VERSION ""

NS_ :

BS_:

BU_:

BO_ 3221225472 VECTOR__INDEPENDENT_SIG_MSG: 0 Vector__XXX
 SG_ ang_heading : 40|16@1- (0.01,0) [-327.68|327.67] "rad" Vector__XXX
 SG_ pos_y : 20|20@1- (0.01,0) [-5242.88|5242.87] "m" Vector__XXX
 SG_ pos_x : 0|20@1- (0.01,0) [-5242.88|5242.87] "m" Vector__XXX
 SG_ yaw_rate : 36|12@1- (0.025,0) [-51.2|51.175] "rps" Vector__XXX
 SG_ velocity_long : 24|12@1- (0.05,0) [-102.4|102.35] "mps" Vector__XXX
 SG_ velocity_lat : 12|12@1- (0.05,0) [-102.4|102.35] "mps" Vector__XXX
 SG_ motor_angle : 48|12@1- (0.5,0) [-255|255] "rad" Vector__XXX
 SG_ acceleration : 0|12@1- (0.025,0) [-51.2|51.175] "mps2" Vector__XXX
 SG_ rc_base_sync_check : 0|1@1+ (1,0) [0|0] "" Vector__XXX
 SG_ rc_lte_rssi : 1|8@1- (1,0) [0|0] "dBm" Vector__XXX
 SG_ duty_cycle_fbk : 48|8@1- (1,0) [-100|100] "%" Vector__XXX
 SG_ duty_cycle_dmd : 40|8@1- (1,0) [-100|100] "%" Vector__XXX
 SG_ steering_motor_ang_avg_fdbk : 0|11@1- (0.5,0) [-1024|1023] "deg" Vector__XXX

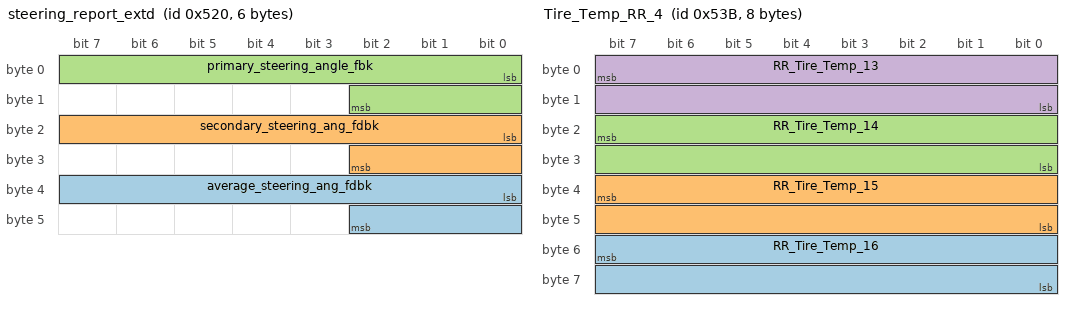
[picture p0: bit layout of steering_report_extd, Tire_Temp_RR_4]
BO_ 1312 steering_report_extd: 6 Vector__XXX
 SG_ average_steering_ang_fdbk : 32|11@1- (0.5,0) [-1024|1023] "deg" Vector__XXX
 SG_ secondary_steering_ang_fdbk : 16|11@1- (0.5,0) [-1024|1023] "deg" Vector__XXX
 SG_ primary_steering_angle_fbk : 0|11@1- (0.5,0) [-1024|1023] "deg" Vector__XXX

BO_ 1339 Tire_Temp_RR_4: 8 Vector__XXX
 SG_ RR_Tire_Temp_16 : 55|16@0+ (0.1,-100) [-100|6453.5] "degC" Vector__XXX
 SG_ RR_Tire_Temp_15 : 39|16@0+ (0.1,-100) [-100|6453.5] "degC" Vector__XXX
 SG_ RR_Tire_Temp_14 : 23|16@0+ (0.1,-100) [-100|6453.5] "degC" Vector__XXX
 SG_ RR_Tire_Temp_13 : 7|16@0+ (0.1,-100) [-100|6453.5] "degC" Vector__XXX

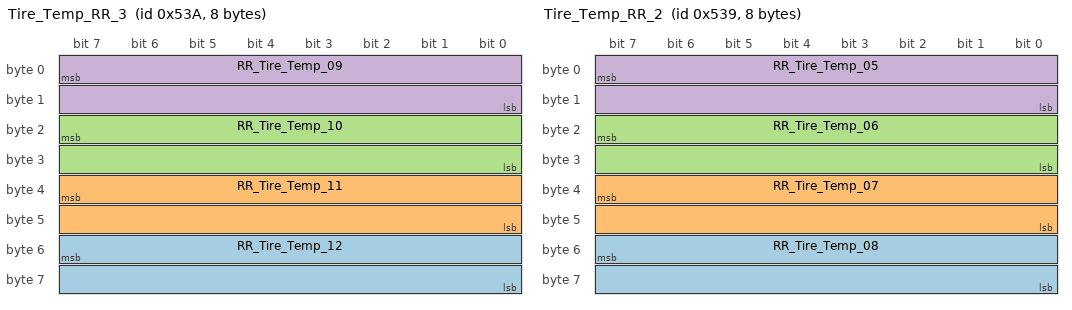
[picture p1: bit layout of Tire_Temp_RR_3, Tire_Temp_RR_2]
BO_ 1338 Tire_Temp_RR_3: 8 Vector__XXX
 SG_ RR_Tire_Temp_12 : 55|16@0+ (0.1,-100) [-100|6453.5] "degC" Vector__XXX
 SG_ RR_Tire_Temp_11 : 39|16@0+ (0.1,-100) [-100|6453.5] "degC" Vector__XXX
 SG_ RR_Tire_Temp_10 : 23|16@0+ (0.1,-100) [-100|6453.5] "degC" Vector__XXX
 SG_ RR_Tire_Temp_09 : 7|16@0+ (0.1,-100) [-100|6453.5] "degC" Vector__XXX

BO_ 1337 Tire_Temp_RR_2: 8 Vector__XXX
 SG_ RR_Tire_Temp_08 : 55|16@0+ (0.1,-100) [-100|6453.5] "degC" Vector__XXX
 SG_ RR_Tire_Temp_07 : 39|16@0+ (0.1,-100) [-100|6453.5] "degC" Vector__XXX
 SG_ RR_Tire_Temp_06 : 23|16@0+ (0.1,-100) [-100|6453.5] "degC" Vector__XXX
 SG_ RR_Tire_Temp_05 : 7|16@0+ (0.1,-100) [-100|6453.5] "degC" Vector__XXX

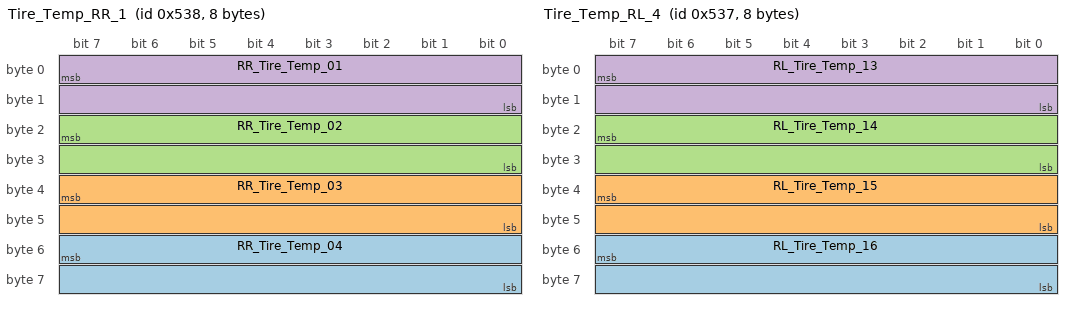
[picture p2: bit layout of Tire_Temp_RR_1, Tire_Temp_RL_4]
BO_ 1336 Tire_Temp_RR_1: 8 Vector__XXX
 SG_ RR_Tire_Temp_04 : 55|16@0+ (0.1,-100) [-100|6453.5] "degC" Vector__XXX
 SG_ RR_Tire_Temp_03 : 39|16@0+ (0.1,-100) [-100|6453.5] "degC" Vector__XXX
 SG_ RR_Tire_Temp_02 : 23|16@0+ (0.1,-100) [-100|6453.5] "degC" Vector__XXX
 SG_ RR_Tire_Temp_01 : 7|16@0+ (0.1,-100) [-100|6453.5] "degC" Vector__XXX

BO_ 1335 Tire_Temp_RL_4: 8 Vector__XXX
 SG_ RL_Tire_Temp_16 : 55|16@0+ (0.1,-100) [-100|6453.5] "degC" Vector__XXX
 SG_ RL_Tire_Temp_15 : 39|16@0+ (0.1,-100) [-100|6453.5] "degC" Vector__XXX
 SG_ RL_Tire_Temp_14 : 23|16@0+ (0.1,-100) [-100|6453.5] "degC" Vector__XXX
 SG_ RL_Tire_Temp_13 : 7|16@0+ (0.1,-100) [-100|6453.5] "degC" Vector__XXX

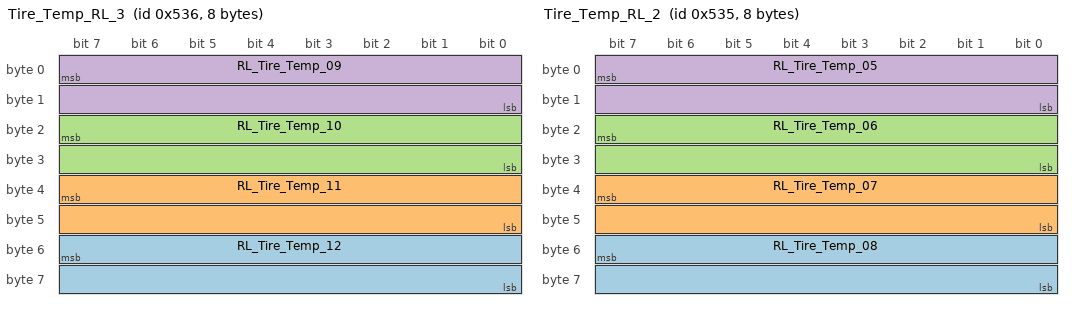
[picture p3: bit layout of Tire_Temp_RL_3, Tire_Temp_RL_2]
BO_ 1334 Tire_Temp_RL_3: 8 Vector__XXX
 SG_ RL_Tire_Temp_12 : 55|16@0+ (0.1,-100) [-100|6453.5] "degC" Vector__XXX
 SG_ RL_Tire_Temp_11 : 39|16@0+ (0.1,-100) [-100|6453.5] "degC" Vector__XXX
 SG_ RL_Tire_Temp_10 : 23|16@0+ (0.1,-100) [-100|6453.5] "degC" Vector__XXX
 SG_ RL_Tire_Temp_09 : 7|16@0+ (0.1,-100) [-100|6453.5] "degC" Vector__XXX

BO_ 1333 Tire_Temp_RL_2: 8 Vector__XXX
 SG_ RL_Tire_Temp_08 : 55|16@0+ (0.1,-100) [-100|6453.5] "degC" Vector__XXX
 SG_ RL_Tire_Temp_07 : 39|16@0+ (0.1,-100) [-100|6453.5] "degC" Vector__XXX
 SG_ RL_Tire_Temp_06 : 23|16@0+ (0.1,-100) [-100|6453.5] "degC" Vector__XXX
 SG_ RL_Tire_Temp_05 : 7|16@0+ (0.1,-100) [-100|6453.5] "degC" Vector__XXX

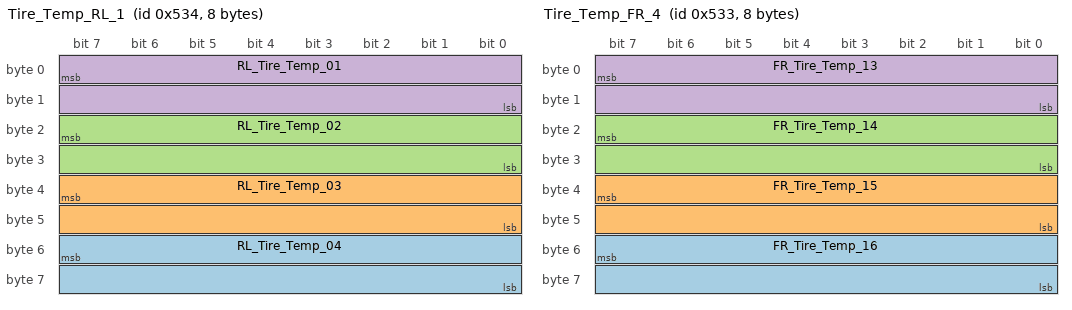
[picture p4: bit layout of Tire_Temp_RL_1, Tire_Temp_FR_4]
BO_ 1332 Tire_Temp_RL_1: 8 Vector__XXX
 SG_ RL_Tire_Temp_04 : 55|16@0+ (0.1,-100) [-100|6453.5] "degC" Vector__XXX
 SG_ RL_Tire_Temp_03 : 39|16@0+ (0.1,-100) [-100|6453.5] "degC" Vector__XXX
 SG_ RL_Tire_Temp_02 : 23|16@0+ (0.1,-100) [-100|6453.5] "degC" Vector__XXX
 SG_ RL_Tire_Temp_01 : 7|16@0+ (0.1,-100) [-100|6453.5] "degC" Vector__XXX

BO_ 1331 Tire_Temp_FR_4: 8 Vector__XXX
 SG_ FR_Tire_Temp_16 : 55|16@0+ (0.1,-100) [-100|6453.5] "degC" Vector__XXX
 SG_ FR_Tire_Temp_15 : 39|16@0+ (0.1,-100) [-100|6453.5] "degC" Vector__XXX
 SG_ FR_Tire_Temp_14 : 23|16@0+ (0.1,-100) [-100|6453.5] "degC" Vector__XXX
 SG_ FR_Tire_Temp_13 : 7|16@0+ (0.1,-100) [-100|6453.5] "degC" Vector__XXX

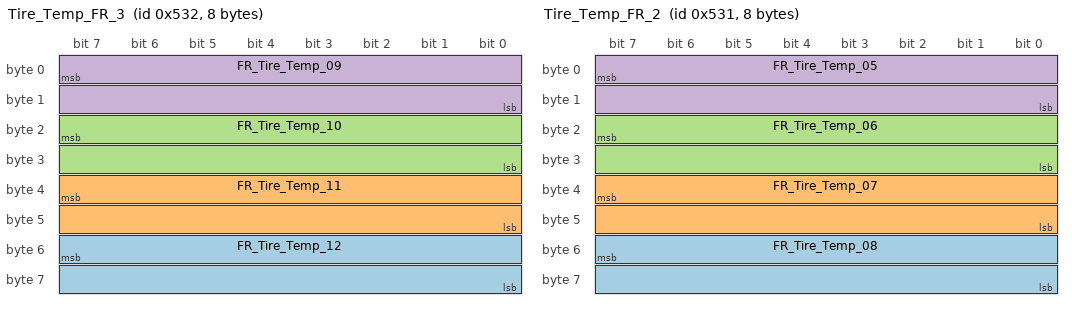
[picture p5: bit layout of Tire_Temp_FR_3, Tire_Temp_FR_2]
BO_ 1330 Tire_Temp_FR_3: 8 Vector__XXX
 SG_ FR_Tire_Temp_12 : 55|16@0+ (0.1,-100) [-100|6453.5] "degC" Vector__XXX
 SG_ FR_Tire_Temp_11 : 39|16@0+ (0.1,-100) [-100|6453.5] "degC" Vector__XXX
 SG_ FR_Tire_Temp_10 : 23|16@0+ (0.1,-100) [-100|6453.5] "degC" Vector__XXX
 SG_ FR_Tire_Temp_09 : 7|16@0+ (0.1,-100) [-100|6453.5] "degC" Vector__XXX

BO_ 1329 Tire_Temp_FR_2: 8 Vector__XXX
 SG_ FR_Tire_Temp_08 : 55|16@0+ (0.1,-100) [-100|6453.5] "degC" Vector__XXX
 SG_ FR_Tire_Temp_07 : 39|16@0+ (0.1,-100) [-100|6453.5] "degC" Vector__XXX
 SG_ FR_Tire_Temp_06 : 23|16@0+ (0.1,-100) [-100|6453.5] "degC" Vector__XXX
 SG_ FR_Tire_Temp_05 : 7|16@0+ (0.1,-100) [-100|6453.5] "degC" Vector__XXX

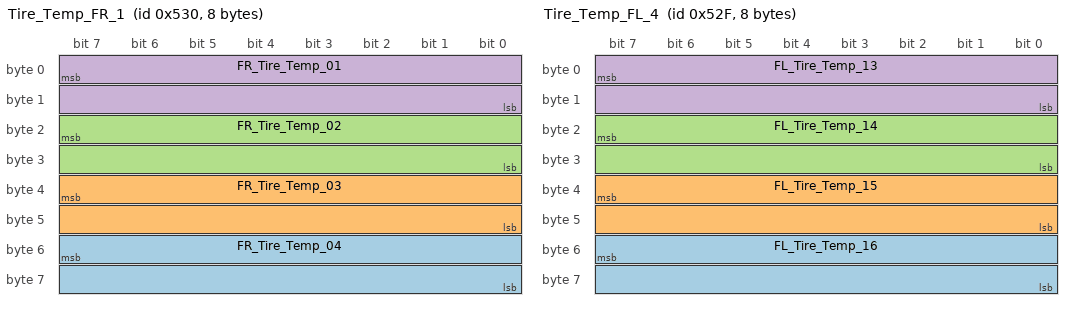
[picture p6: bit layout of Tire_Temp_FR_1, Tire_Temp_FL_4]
BO_ 1328 Tire_Temp_FR_1: 8 Vector__XXX
 SG_ FR_Tire_Temp_04 : 55|16@0+ (0.1,-100) [-100|6453.5] "degC" Vector__XXX
 SG_ FR_Tire_Temp_03 : 39|16@0+ (0.1,-100) [-100|6453.5] "degC" Vector__XXX
 SG_ FR_Tire_Temp_02 : 23|16@0+ (0.1,-100) [-100|6453.5] "degC" Vector__XXX
 SG_ FR_Tire_Temp_01 : 7|16@0+ (0.1,-100) [-100|6453.5] "degC" Vector__XXX

BO_ 1327 Tire_Temp_FL_4: 8 Vector__XXX
 SG_ FL_Tire_Temp_16 : 55|16@0+ (0.1,-100) [-100|6453.5] "degC" Vector__XXX
 SG_ FL_Tire_Temp_15 : 39|16@0+ (0.1,-100) [-100|6453.5] "degC" Vector__XXX
 SG_ FL_Tire_Temp_14 : 23|16@0+ (0.1,-100) [-100|6453.5] "degC" Vector__XXX
 SG_ FL_Tire_Temp_13 : 7|16@0+ (0.1,-100) [-100|6453.5] "degC" Vector__XXX

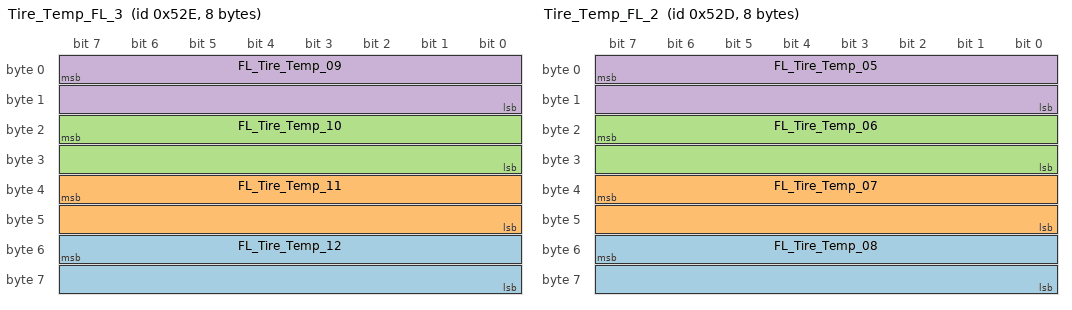
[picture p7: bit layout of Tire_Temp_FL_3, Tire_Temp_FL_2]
BO_ 1326 Tire_Temp_FL_3: 8 Vector__XXX
 SG_ FL_Tire_Temp_12 : 55|16@0+ (0.1,-100) [-100|6453.5] "degC" Vector__XXX
 SG_ FL_Tire_Temp_11 : 39|16@0+ (0.1,-100) [-100|6453.5] "degC" Vector__XXX
 SG_ FL_Tire_Temp_10 : 23|16@0+ (0.1,-100) [-100|6453.5] "degC" Vector__XXX
 SG_ FL_Tire_Temp_09 : 7|16@0+ (0.1,-100) [-100|6453.5] "degC" Vector__XXX

BO_ 1325 Tire_Temp_FL_2: 8 Vector__XXX
 SG_ FL_Tire_Temp_08 : 55|16@0+ (0.1,-100) [-100|6453.5] "degC" Vector__XXX
 SG_ FL_Tire_Temp_07 : 39|16@0+ (0.1,-100) [-100|6453.5] "degC" Vector__XXX
 SG_ FL_Tire_Temp_06 : 23|16@0+ (0.1,-100) [-100|6453.5] "degC" Vector__XXX
 SG_ FL_Tire_Temp_05 : 7|16@0+ (0.1,-100) [-100|6453.5] "degC" Vector__XXX

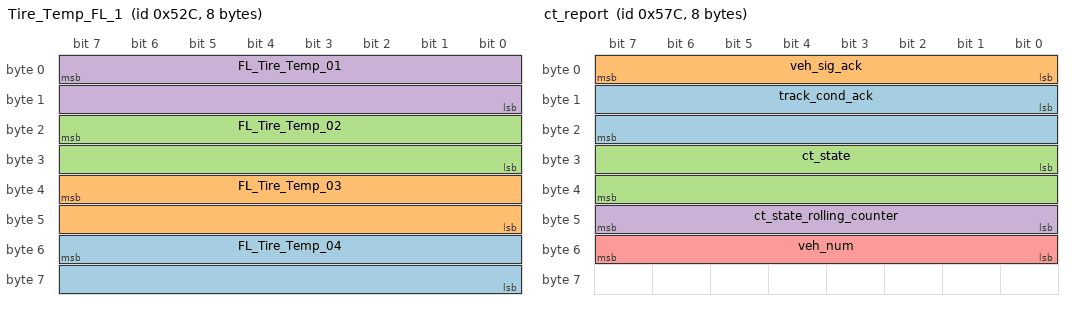
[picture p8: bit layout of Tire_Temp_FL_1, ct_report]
BO_ 1324 Tire_Temp_FL_1: 8 Vector__XXX
 SG_ FL_Tire_Temp_04 : 55|16@0+ (0.1,-100) [-100|6453.5] "degC" Vector__XXX
 SG_ FL_Tire_Temp_03 : 39|16@0+ (0.1,-100) [-100|6453.5] "degC" Vector__XXX
 SG_ FL_Tire_Temp_02 : 23|16@0+ (0.1,-100) [-100|6453.5] "degC" Vector__XXX
 SG_ FL_Tire_Temp_01 : 7|16@0+ (0.1,-100) [-100|6453.5] "degC" Vector__XXX

BO_ 1323 Tire_Pressure_RR: 4 Vector__XXX
 SG_ RR_Tire_Pressure_Gauge : 23|16@0+ (1,0) [0|65535] "mbar" Vector__XXX
 SG_ RR_Tire_Pressure : 7|16@0+ (1,0) [0|65535] "mbar" Vector__XXX

BO_ 1322 Tire_Pressure_RL: 4 Vector__XXX
 SG_ RL_Tire_Pressure_Gauge : 23|16@0+ (1,0) [0|65535] "mbar" Vector__XXX
 SG_ RL_Tire_Pressure : 7|16@0+ (1,0) [0|65535] "mbar" Vector__XXX

BO_ 1321 Tire_Pressure_FR: 4 Vector__XXX
 SG_ FR_Tire_Pressure_Gauge : 23|16@0+ (1,0) [0|65535] "mbar" Vector__XXX
 SG_ FR_Tire_Pressure : 7|16@0+ (1,0) [0|65535] "mbar" Vector__XXX

BO_ 1320 Tire_Pressure_FL: 4 Vector__XXX
 SG_ FL_Tire_Pressure_Gauge : 23|16@0+ (1,0) [0|65535] "mbar" Vector__XXX
 SG_ FL_Tire_Pressure : 7|16@0+ (1,0) [0|65535] "mbar" Vector__XXX

BO_ 1403 gear_shift_cmd: 8 Vector__XXX
 SG_ desired_gear : 0|8@1+ (1,0) [0|0] "" Vector__XXX

BO_ 1404 ct_report: 8 Vector__XXX
 SG_ track_cond_ack : 8|16@1+ (1,0) [0|0] "" Vector__XXX
 SG_ veh_sig_ack : 0|8@1+ (1,0) [0|0] "" Vector__XXX
 SG_ ct_state : 24|16@1+ (1,0) [0|0] "" Vector__XXX
 SG_ ct_state_rolling_counter : 40|8@1+ (1,0) [0|9] "" Vector__XXX
 SG_ veh_num : 48|8@1+ (1,0) [0|0] "" Vector__XXX

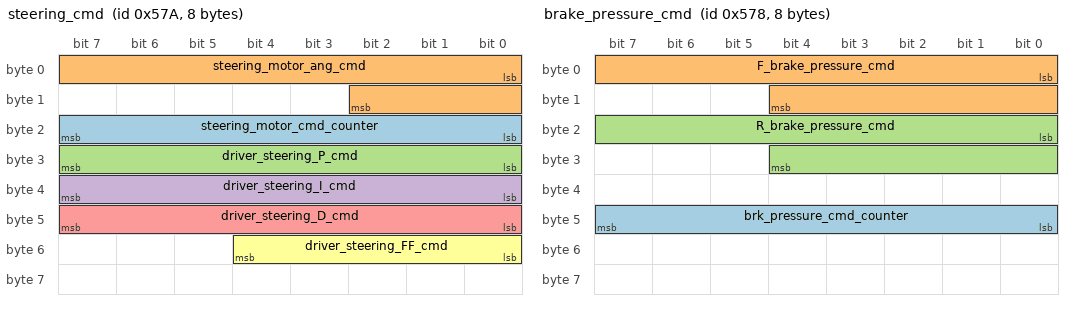
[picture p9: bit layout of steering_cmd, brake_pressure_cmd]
BO_ 1402 steering_cmd: 8 Vector__XXX
 SG_ steering_motor_cmd_counter : 16|8@1+ (1,0) [0|255] "" Vector__XXX
 SG_ steering_motor_ang_cmd : 0|11@1- (0.5,0) [-1024|1023] "deg" Vector__XXX
 SG_ driver_steering_P_cmd : 24|8@1+ (0.1,0) [0|0] "" Vector__XXX
 SG_ driver_steering_I_cmd : 32|8@1+ (0.1,0) [0|0] "" Vector__XXX
 SG_ driver_steering_D_cmd : 40|8@1+ (0.01,0) [0|0] "" Vector__XXX
 SG_ driver_steering_FF_cmd : 48|5@1+ (0.1,0) [0|3.1] "" Vector__XXX

BO_ 1401 accelerator_cmd: 8 Vector__XXX
 SG_ acc_pedal_cmd_counter : 16|8@1+ (1,0) [0|255] "" Vector__XXX
 SG_ acc_pedal_cmd : 0|16@1- (0.01,0) [-150|655.35] "%" Vector__XXX

BO_ 1400 brake_pressure_cmd: 8 Vector__XXX
 SG_ brk_pressure_cmd_counter : 40|8@1+ (1,0) [0|255] "" Vector__XXX
 SG_ F_brake_pressure_cmd : 0|13@1+ (1,0) [0|8191] "" Vector__XXX
 SG_ R_brake_pressure_cmd : 16|13@1+ (1,0) [0|8191] "" Vector__XXX

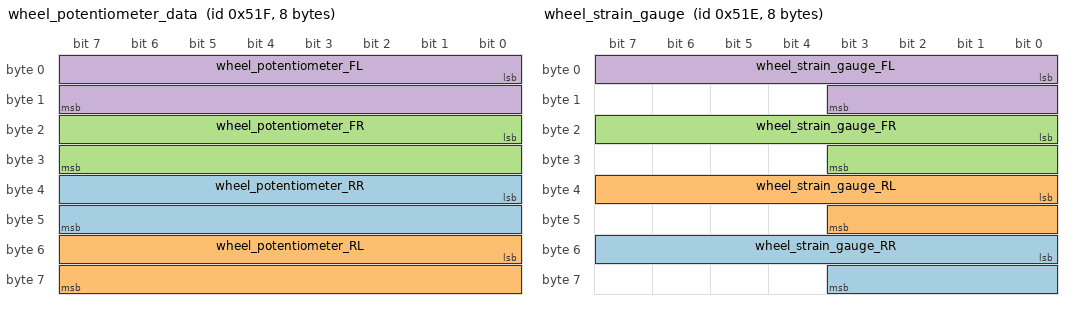
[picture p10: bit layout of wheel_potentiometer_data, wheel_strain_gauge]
BO_ 1311 wheel_potentiometer_data: 8 Vector__XXX
 SG_ wheel_potentiometer_RR : 32|16@1+ (0.01,0) [0|0] "" Vector__XXX
 SG_ wheel_potentiometer_RL : 48|16@1+ (0.01,0) [0|0] "" Vector__XXX
 SG_ wheel_potentiometer_FR : 16|16@1+ (0.01,0) [0|0] "" Vector__XXX
 SG_ wheel_potentiometer_FL : 0|16@1+ (0.01,0) [0|0] "" Vector__XXX

BO_ 1310 wheel_strain_gauge: 8 Vector__XXX
 SG_ wheel_strain_gauge_RR : 48|12@1+ (10,0) [0|8190] "" Vector__XXX
 SG_ wheel_strain_gauge_RL : 32|12@1+ (10,0) [0|8190] "" Vector__XXX
 SG_ wheel_strain_gauge_FR : 16|12@1+ (10,0) [0|8190] "" Vector__XXX
 SG_ wheel_strain_gauge_FL : 0|12@1+ (10,0) [0|8190] "" Vector__XXX

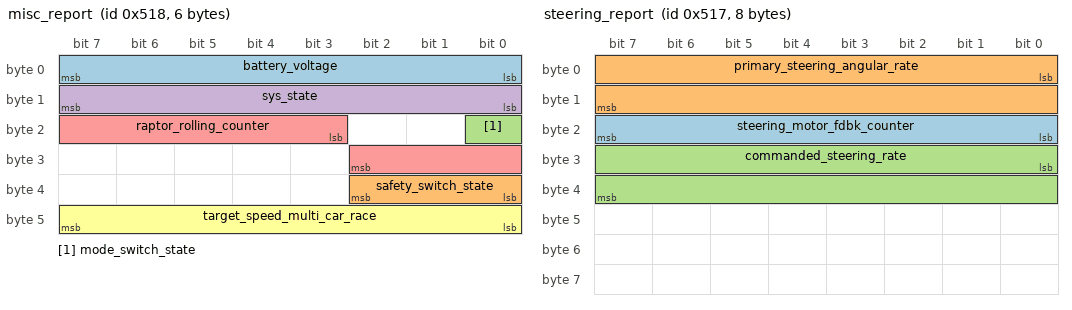
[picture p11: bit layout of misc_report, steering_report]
BO_ 1304 misc_report: 6 Vector__XXX
 SG_ battery_voltage : 0|8@1+ (0.1,0) [0|0] "V" Vector__XXX
 SG_ safety_switch_state : 32|3@1+ (1,0) [0|0] "" Vector__XXX
 SG_ mode_switch_state : 16|1@1+ (1,0) [0|0] "" Vector__XXX
 SG_ sys_state : 8|8@1+ (1,0) [0|0] "" Vector__XXX
 SG_ raptor_rolling_counter : 19|8@1+ (1,0) [0|0] "" Vector__XXX
 SG_ target_speed_multi_car_race : 40|8@1+ (1,0) [0|0] "mph" Vector__XXX

BO_ 1303 steering_report: 8 Vector__XXX
 SG_ steering_motor_fdbk_counter : 16|8@1+ (1,0) [0|255] "" Vector__XXX
 SG_ primary_steering_angular_rate : 0|16@1- (0.1,0) [0|0] "deg/s" Vector__XXX
 SG_ commanded_steering_rate : 24|16@1- (0.1,0) [0|0] "deg/s" Vector__XXX

BO_ 1302 accelerator_report: 3 Vector__XXX
 SG_ acc_pedal_fdbk_counter : 16|8@1+ (1,0) [0|255] "" Vector__XXX
 SG_ acc_pedal_fdbk : 0|16@1+ (0.1,0) [0|65535] "%" Vector__XXX

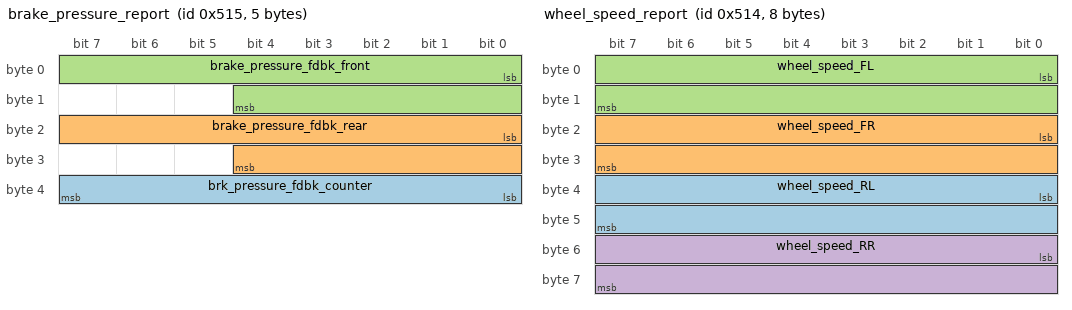
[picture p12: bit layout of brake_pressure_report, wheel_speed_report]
BO_ 1301 brake_pressure_report: 5 Vector__XXX
 SG_ brk_pressure_fdbk_counter : 32|8@1+ (1,0) [0|255] "" Vector__XXX
 SG_ brake_pressure_fdbk_rear : 16|13@1+ (1,0) [0|8191] "kPa" Vector__XXX
 SG_ brake_pressure_fdbk_front : 0|13@1+ (1,0) [0|8191] "kPa" Vector__XXX

BO_ 1300 wheel_speed_report: 8 Vector__XXX
 SG_ wheel_speed_RL : 32|16@1+ (0.1,0) [0|340] "kmph" Vector__XXX
 SG_ wheel_speed_FR : 16|16@1+ (0.1,0) [0|340] "kmph" Vector__XXX
 SG_ wheel_speed_FL : 0|16@1+ (0.1,0) [0|340] "kmph" Vector__XXX
 SG_ wheel_speed_RR : 48|16@1+ (0.1,0) [0|340] "kmph" Vector__XXX

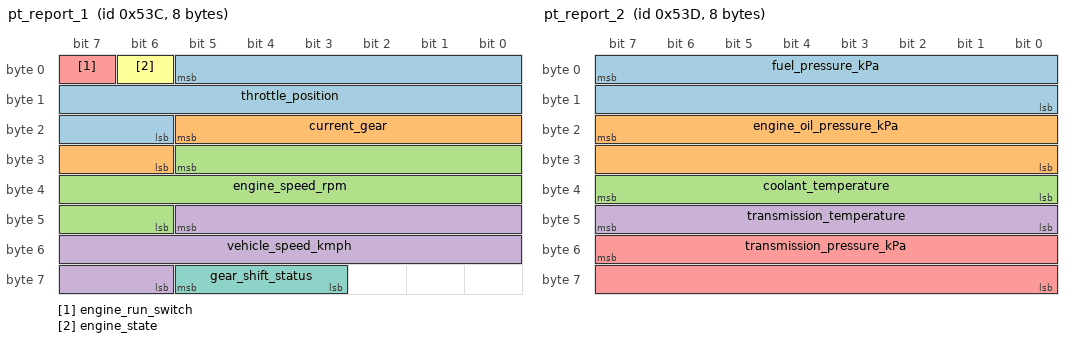
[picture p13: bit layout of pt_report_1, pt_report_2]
BO_ 1340 pt_report_1: 8 Vector__XXX
 SG_ throttle_position : 5|16@0+ (0.1,0) [0|100] "%" Vector__XXX
 SG_ current_gear : 21|8@0+ (1,0) [0|0] "" Vector__XXX
 SG_ engine_speed_rpm : 29|16@0+ (1,0) [0|16000] "rpm" Vector__XXX
 SG_ vehicle_speed_kmph : 45|16@0+ (0.1,0) [0|6553.5] "kmph" Vector__XXX
 SG_ engine_run_switch : 7|1@0+ (1,0) [0|0] "" Vector__XXX
 SG_ engine_state : 6|1@0+ (1,0) [0|0] "" Vector__XXX
 SG_ gear_shift_status : 61|3@0+ (1,0) [0|0] "" Vector__XXX

BO_ 1341 pt_report_2: 8 Vector__XXX
 SG_ fuel_pressure_kPa : 7|16@0+ (0.1,0) [0|1000] "kPa" Vector__XXX
 SG_ engine_oil_pressure_kPa : 23|16@0+ (0.1,0) [0|0] "kPa" Vector__XXX
 SG_ coolant_temperature : 39|8@0+ (1,0) [0|255] "C" Vector__XXX
 SG_ transmission_temperature : 47|8@0+ (1,0) [0|255] "C" Vector__XXX
 SG_ transmission_pressure_kPa : 55|16@0+ (1,0) [0|0] "kPa" Vector__XXX

BO_ 1342 diagnostic_report: 8 Vector__XXX
 SG_ sd_system_warning : 0|1@1+ (1,0) [0|0] "" Vector__XXX
 SG_ sd_system_failure : 1|1@1+ (1,0) [0|0] "" Vector__XXX
 SG_ sd_brake_warning1 : 2|1@1+ (1,0) [0|0] "" Vector__XXX
 SG_ sd_brake_warning2 : 3|1@1+ (1,0) [0|0] "" Vector__XXX
 SG_ sd_brake_warning3 : 4|1@1+ (1,0) [0|0] "" Vector__XXX
 SG_ sd_steer_warning1 : 5|1@1+ (1,0) [0|0] "" Vector__XXX
 SG_ sd_steer_warning2 : 6|1@1+ (1,0) [0|0] "" Vector__XXX
 SG_ sd_steer_warning3 : 7|1@1+ (1,0) [0|0] "" Vector__XXX
 SG_ motec_warning : 8|8@1+ (1,0) [0|31] "" Vector__XXX
 SG_ est1_oos_front_brk : 16|1@1+ (1,0) [0|0] "" Vector__XXX
 SG_ est2_oos_rear_brk : 17|1@1+ (1,0) [0|0] "" Vector__XXX
 SG_ est3_low_eng_speed : 18|1@1+ (1,0) [0|0] "" Vector__XXX
 SG_ est4_sd_comms_loss : 19|1@1+ (1,0) [0|0] "" Vector__XXX
 SG_ est5_motec_comms_loss : 20|1@1+ (1,0) [0|0] "" Vector__XXX
 SG_ est6_sd_ebrake : 21|1@1+ (1,0) [0|0] "" Vector__XXX
 SG_ adlink_hb_lost : 22|1@1+ (1,0) [0|0] "" Vector__XXX
 SG_ rc_lost : 23|1@1+ (1,0) [0|0] "" Vector__XXX

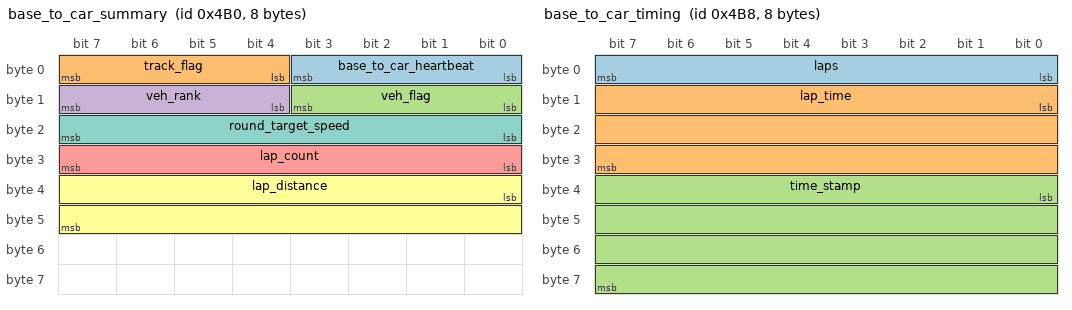
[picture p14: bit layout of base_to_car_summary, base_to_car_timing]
BO_ 1200 base_to_car_summary: 8 Vector__XXX
 SG_ base_to_car_heartbeat : 0|4@1+ (1,0) [0|0] "" Vector__XXX
 SG_ track_flag : 4|4@1+ (1,0) [0|0] "" Vector__XXX
 SG_ veh_flag : 8|4@1+ (1,0) [0|0] "" Vector__XXX
 SG_ veh_rank : 12|4@1+ (1,0) [0|0] "" Vector__XXX
 SG_ lap_count : 24|8@1+ (1,0) [0|0] "" Vector__XXX
 SG_ lap_distance : 32|16@1+ (1,0) [0|0] "m" Vector__XXX
 SG_ round_target_speed : 16|8@1+ (1,0) [0|0] "mph" Vector__XXX

BO_ 1208 base_to_car_timing: 8 Vector__XXX
 SG_ laps : 0|8@1+ (1,0) [0|0] "" Vector__XXX
 SG_ lap_time : 8|24@1+ (0.1,0) [0|0] "ms" Vector__XXX
 SG_ time_stamp : 32|32@1+ (0.1,0) [0|0] "ms" Vector__XXX

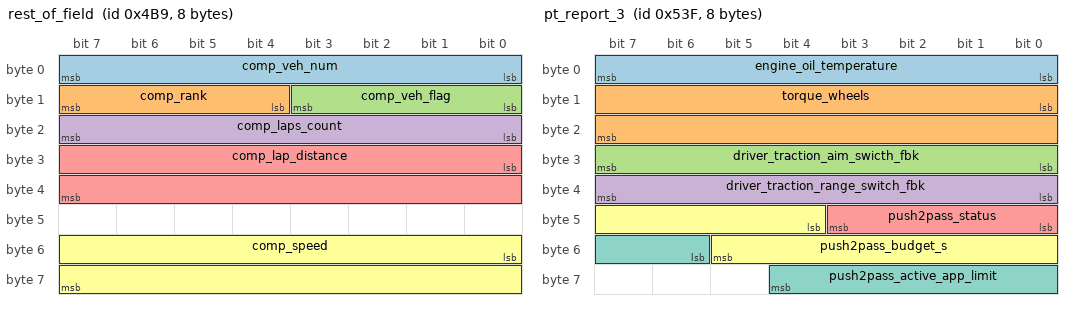
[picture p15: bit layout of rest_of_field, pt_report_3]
BO_ 1209 rest_of_field: 8 Vector__XXX
 SG_ comp_veh_num : 0|8@1+ (1,0) [0|0] "" Vector__XXX
 SG_ comp_rank : 12|4@1+ (1,0) [0|0] "" Vector__XXX
 SG_ comp_veh_flag : 8|4@1+ (1,0) [0|0] "" Vector__XXX
 SG_ comp_laps_count : 16|8@1+ (1,0) [0|0] "" Vector__XXX
 SG_ comp_lap_distance : 24|16@1+ (1,0) [0|0] "m" Vector__XXX
 SG_ comp_speed : 48|16@1+ (0.1,0) [0|0] "kmph" Vector__XXX

BO_ 1343 pt_report_3: 8 Vector__XXX
 SG_ engine_oil_temperature : 0|8@1+ (1,0) [0|0] "degC" Vector__XXX
 SG_ torque_wheels : 8|16@1- (0.1,0) [0|0] "Nm" Vector__XXX
 SG_ driver_traction_aim_swicth_fbk : 24|8@1- (1,0) [0|0] "" Vector__XXX
 SG_ driver_traction_range_switch_fbk : 32|8@1- (1,0) [0|0] "" Vector__XXX
 SG_ push2pass_status : 40|4@1+ (1,0) [0|0] "" Vector__XXX
 SG_ push2pass_budget_s : 44|10@1+ (1,0) [0|0] "s" Vector__XXX
 SG_ push2pass_active_app_limit : 54|7@1+ (1,0) [0|100] "%" Vector__XXX

BO_ 228 mylaps_report_1: 8 Vector__XXX
 SG_ mylaps_speed : 0|16@1+ (1,0) [0|0] "kmph" Vector__XXX
 SG_ mylaps_heading : 16|16@1- (1,0) [0|0] "degrees" Vector__XXX

BO_ 226 mylaps_report_2: 8 Vector__XXX
 SG_ Latitude : 0|32@1- (1e-07,0) [0|0] "" Vector__XXX
 SG_ Longitude : 32|32@1- (1e-07,0) [0|0] "" Vector__XXX

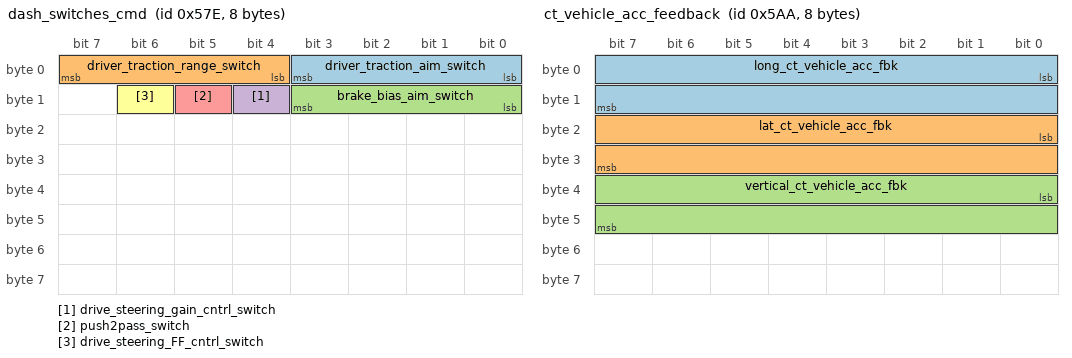
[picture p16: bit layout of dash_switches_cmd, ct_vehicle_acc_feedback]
BO_ 1406 dash_switches_cmd: 8 Vector__XXX
 SG_ driver_traction_aim_switch : 0|4@1+ (1,0) [0|0] "" Vector__XXX
 SG_ driver_traction_range_switch : 4|4@1+ (1,0) [0|0] "" Vector__XXX
 SG_ brake_bias_aim_switch : 8|4@1+ (1,0) [0|0] "" Vector__XXX
 SG_ drive_steering_gain_cntrl_switch : 12|1@1+ (1,0) [0|1] "" Vector__XXX
 SG_ push2pass_switch : 13|1@1+ (1,0) [0|0] "" Vector__XXX
 SG_ drive_steering_FF_cntrl_switch : 14|1@1+ (1,0) [0|0] "" Vector__XXX

BO_ 1450 ct_vehicle_acc_feedback: 8 Vector__XXX
 SG_ long_ct_vehicle_acc_fbk : 0|16@1- (0.01,0) [-327.68|327.67] "G" Vector__XXX
 SG_ lat_ct_vehicle_acc_fbk : 16|16@1- (0.01,0) [-327.68|327.67] "G" Vector__XXX
 SG_ vertical_ct_vehicle_acc_fbk : 32|16@1- (0.01,0) [-327.68|327.67] "G" Vector__XXX

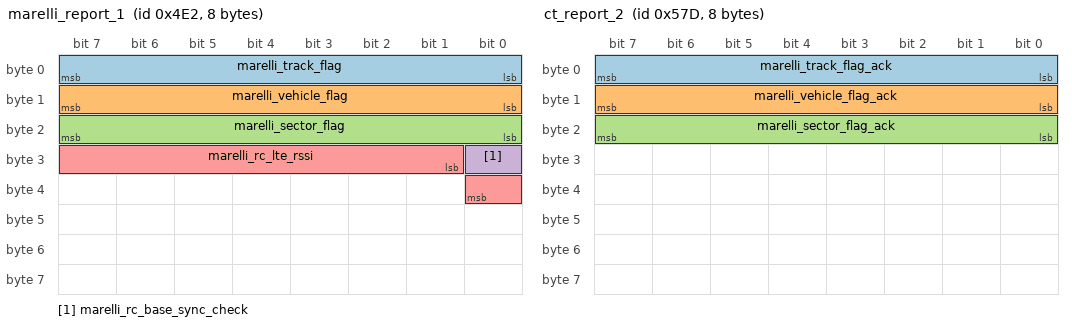
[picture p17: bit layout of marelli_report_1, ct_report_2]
BO_ 1250 marelli_report_1: 8 Vector__XXX
 SG_ marelli_track_flag : 0|8@1+ (1,0) [0|0] "" Vector__XXX
 SG_ marelli_vehicle_flag : 8|8@1+ (1,0) [0|0] "" Vector__XXX
 SG_ marelli_sector_flag : 16|8@1+ (1,0) [0|0] "" Vector__XXX
 SG_ marelli_rc_base_sync_check : 24|1@1+ (1,0) [0|0] "" Vector__XXX
 SG_ marelli_rc_lte_rssi : 25|8@1- (1,0) [0|0] "" Vector__XXX

BO_ 1251 marelli_report_2: 8 Vector__XXX
 SG_ marelli_gps_lat : 0|32@1- (1e-07,0) [0|0] "°" Vector__XXX
 SG_ marelli_gps_long : 32|32@1- (1e-07,0) [0|0] "°" Vector__XXX

BO_ 1405 ct_report_2: 8 Vector__XXX
 SG_ marelli_track_flag_ack : 0|8@1+ (1,0) [0|0] "" Vector__XXX
 SG_ marelli_vehicle_flag_ack : 8|8@1+ (1,0) [0|0] "" Vector__XXX
 SG_ marelli_sector_flag_ack : 16|8@1+ (1,0) [0|0] "" Vector__XXX

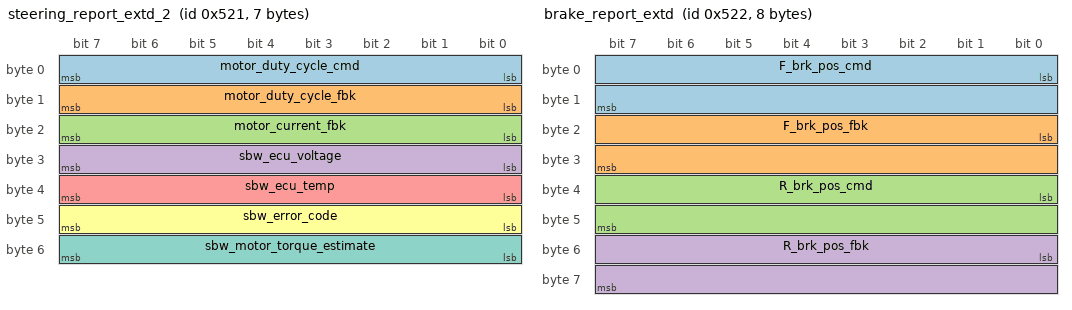
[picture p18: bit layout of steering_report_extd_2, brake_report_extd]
BO_ 1313 steering_report_extd_2: 7 Vector__XXX
 SG_ motor_duty_cycle_cmd : 0|8@1- (1,0) [-100|100] "%" Vector__XXX
 SG_ motor_duty_cycle_fbk : 8|8@1- (1,0) [-100|100] "%" Vector__XXX
 SG_ motor_current_fbk : 16|8@1+ (1,0) [0|128] "A" Vector__XXX
 SG_ sbw_ecu_voltage : 24|8@1+ (0.1,0) [0|25.5] "V" Vector__XXX
 SG_ sbw_ecu_temp : 32|8@1+ (1,0) [0|130] "degC" Vector__XXX
 SG_ sbw_error_code : 40|8@1+ (1,0) [0|120] "" Vector__XXX
 SG_ sbw_motor_torque_estimate : 48|8@1+ (1,0) [0|110] "Nm" Vector__XXX

BO_ 1314 brake_report_extd: 8 Vector__XXX
 SG_ F_brk_pos_cmd : 0|16@1+ (-0.354,7500) [0|15000] "" Vector__XXX
 SG_ F_brk_pos_fbk : 16|16@1+ (1,0) [0|15000] "" Vector__XXX
 SG_ R_brk_pos_cmd : 32|16@1+ (-0.354,7500) [0|15000] "" Vector__XXX
 SG_ R_brk_pos_fbk : 48|16@1+ (1,0) [0|15000] "" Vector__XXX

BO_ 1315 brake_report_extd_2: 4 Vector__XXX
 SG_ f_brake_act_force : 0|12@1+ (1,0) [0|3000] "N" Vector__XXX
 SG_ r_brake_act_force : 16|12@1+ (1,0) [0|3000] "N" Vector__XXX

BO_ 1350 novatel_report: 8 Vector__XXX
 SG_ novatel_lat : 0|32@1- (1e-07,0) [0|0] "deg" Vector__XXX
 SG_ novatel_long : 32|32@1- (1e-07,0) [0|0] "deg" Vector__XXX

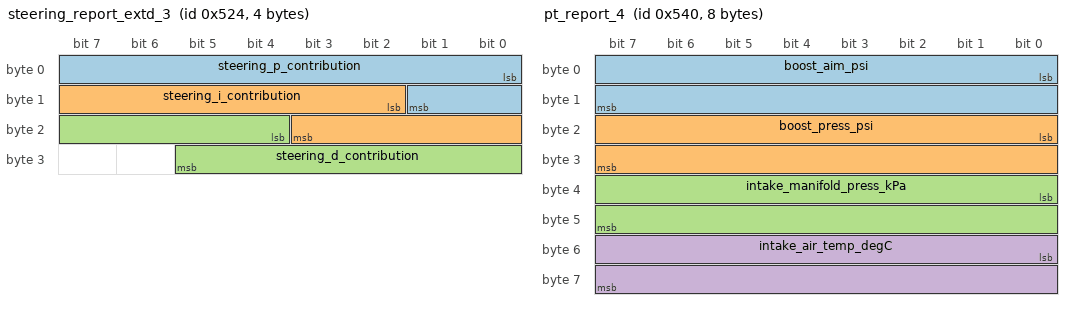
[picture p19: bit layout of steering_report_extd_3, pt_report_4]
BO_ 1316 steering_report_extd_3: 4 Vector__XXX
 SG_ steering_p_contribution : 0|10@1- (1,0) [0|0] "%" Vector__XXX
 SG_ steering_i_contribution : 10|10@1- (1,0) [0|0] "%" Vector__XXX
 SG_ steering_d_contribution : 20|10@1- (1,0) [0|0] "%" Vector__XXX

BO_ 1344 pt_report_4: 8 Vector__XXX
 SG_ boost_aim_psi : 0|16@1+ (0.1,0) [0|35] "psi" Vector__XXX
 SG_ boost_press_psi : 16|16@1- (0.1,0) [-1|35] "psi" Vector__XXX
 SG_ intake_manifold_press_kPa : 32|16@1- (0.1,0) [0|500] "kPa" Vector__XXX
 SG_ intake_air_temp_degC : 48|16@1- (0.1,0) [-40|120] "degC" Vector__XXX

CM_ SG_ 3221225472 duty_cycle_fbk "duty cycle fbk from SBW";
CM_ SG_ 3221225472 duty_cycle_dmd "duty cycle commanded by raptor";
CM_ SG_ 3221225472 steering_motor_ang_avg_fdbk "motor angle feedback in deg.

physical_value = offset + factor * raw_value_decimal";
CM_ SG_ 1312 average_steering_ang_fdbk "average (primary & secondary) steering angle feedback in deg.

physical_value = offset + factor * raw_value_decimal";
CM_ SG_ 1312 secondary_steering_ang_fdbk "secondary steering angle feedback in deg.

physical_value = offset + factor * raw_value_decimal";
CM_ SG_ 1312 primary_steering_angle_fbk "primary steering angle feedback in deg.

physical_value = offset + factor * raw_value_decimal";
CM_ BO_ 1403 "DO12 - gear shift command";
CM_ BO_ 1404 "DO12 - CT report to RC ";
CM_ BO_ 1402 "steering demand from computer to raptor in degrees
";
CM_ SG_ 1402 steering_motor_cmd_counter "rolling counter for steering motor angle commamd message";
CM_ SG_ 1402 steering_motor_ang_cmd "motor angle command  in deg.

physical_value = offset + factor * raw_value_decimal";
CM_ SG_ 1402 driver_steering_P_cmd "driver setting of P (Proportional) gain for the steering controller hosted on raptor";
CM_ SG_ 1402 driver_steering_I_cmd "driver setting of I (Integral) gain for the steering controller hosted on raptor";
CM_ SG_ 1402 driver_steering_D_cmd "driver setting of D (Derivative) gain for the steering controller hosted on raptor";
CM_ SG_ 1402 driver_steering_FF_cmd "driver setting of FF gain. FF gain gets multiplied to the duty cycle output of the FF table on raptor.
FF table on raptor is linear interpolation of 
-100% to +100% corresponding -720 deg/s to +720 deg/s (Which is the maximum no load RPM of the motor) 
The table is also adjustible but not online
";
CM_ SG_ 1401 acc_pedal_cmd "0-100 % accelerator pedal
";
CM_ BO_ 1400 "Demand of brake pressure from computer to raptor in kPa
";
CM_ SG_ 1400 brk_pressure_cmd_counter "rolling counter for brake pressure command message";
CM_ SG_ 1400 F_brake_pressure_cmd "Brake pressure for front wheels in kPa. demand from competition team
values should be positive integer in kPa.";
CM_ SG_ 1400 R_brake_pressure_cmd "Brake pressure for rear wheels in kPa. demand from competition team
values should be positive integer in kPa.";
CM_ BO_ 1311 "Contains the information of potentiometer, pot readings are currently quantized to 0.01 mm. To be later switched to two different channels:
a) Calibrated to damper travel 
b) Calibrated to corner loads ";
CM_ SG_ 1311 wheel_potentiometer_RR "potentiometer reading of front left assembly";
CM_ SG_ 1311 wheel_potentiometer_RL "potentiometer reading of front left assembly";
CM_ SG_ 1311 wheel_potentiometer_FR "potentiometer reading of front left assembly";
CM_ SG_ 1311 wheel_potentiometer_FL "potentiometer reading of front left assembly";
CM_ BO_ 1310 "Contains the information of strain gauges, strain gauge info currently sent as a mV sensor value.
To be later switched to calibrated corner load values. Mapped each time during setup.";
CM_ SG_ 1310 wheel_strain_gauge_RR "strain gauge load value in N rear right wheel  in mm.
";
CM_ SG_ 1310 wheel_strain_gauge_RL "strain gauge load value in N rear left wheel  in mm.
";
CM_ SG_ 1310 wheel_strain_gauge_FR "strain gauge load value in N front right wheel  in mm.
";
CM_ SG_ 1310 wheel_strain_gauge_FL "strain gauge load value in N front left wheel in mm.
";
CM_ BO_ 1304 "DO12 - misc report";
CM_ SG_ 1304 target_speed_multi_car_race "This signal outputs expected speed from the car when running in multicar race with push2pass rules. Not to implemented unless communicated. This is a backup strategy in case if we think throttle saturation based P2P is not viable.

This speed request will ONLY switch between floor and ceiling speeds as directed by the P2P state machine. Unit will be in MPH  ";
CM_ SG_ 1303 steering_motor_fdbk_counter "rolling counter for steering motor angle feedbak message";
CM_ SG_ 1303 primary_steering_angular_rate "Steering Rate based on Primary Steering Angle Feedback - Not filtered/ using discrete derivative
";
CM_ BO_ 1301 "Brake pressure for front and rear wheels in kPa. ";
CM_ SG_ 1301 brk_pressure_fdbk_counter "rolling counter for brake pressure feedback message";
CM_ SG_ 1301 brake_pressure_fdbk_rear "Brake pressure for rear wheels in kPa. 
values will be positive integer in kPa.";
CM_ SG_ 1301 brake_pressure_fdbk_front "Brake pressure for front wheels in kPa. 
values will be positive integer in kPa.";
CM_ SG_ 1300 wheel_speed_RL "rear left wheel speed in kmph
";
CM_ SG_ 1300 wheel_speed_FR "front right wheel speed in kmph";
CM_ SG_ 1300 wheel_speed_FL "front left wheel speed in kmph";
CM_ SG_ 1300 wheel_speed_RR "rear right wheel speed in kmph";
CM_ SG_ 1340 engine_run_switch "Run swicth 1 implies fuel pumps are on and primed/priming;
Run switch 0 implies pumps are off;
";
CM_ SG_ 1340 engine_state "Engine state 1 implies that the engine is running; 
Engine state 0 implies that it is off;";
CM_ SG_ 1340 gear_shift_status "0 = Uninitialised; 1 = Ready to shift; 2= Locked Out; 3= Upshift in progress;
4= Downshift in progress; ";
CM_ SG_ 1342 sd_system_warning "0 means okay; 
1 means error;
";
CM_ SG_ 1342 sd_system_failure "0 means okay; 
1 means error;

";
CM_ SG_ 1342 sd_brake_warning1 "0 means okay; 
1 means error;
";
CM_ SG_ 1342 sd_brake_warning2 "0 means okay; 
1 means error;
";
CM_ SG_ 1342 sd_brake_warning3 "0 means okay; 
1 means error;
";
CM_ SG_ 1342 sd_steer_warning1 "0 means okay; 
1 means error;
";
CM_ SG_ 1342 sd_steer_warning2 "0 means okay; 
1 means error;
";
CM_ SG_ 1342 sd_steer_warning3 "0 means okay; 
1 means error;
";
CM_ SG_ 1342 motec_warning "0 means okay; 
1 means error;
";
CM_ SG_ 1342 est1_oos_front_brk "0 means okay; 
1 means error;
";
CM_ SG_ 1342 est2_oos_rear_brk "0 means okay; 
1 means error;
";
CM_ SG_ 1342 est3_low_eng_speed "0 means okay; 
1 means error;
";
CM_ SG_ 1342 est4_sd_comms_loss "0 means okay; 
1 means error;
";
CM_ SG_ 1342 est5_motec_comms_loss "0 means okay; 
1 means error;
";
CM_ SG_ 1342 est6_sd_ebrake "0 means okay; 
1 means error;
";
CM_ SG_ 1342 adlink_hb_lost "0--HB okay;
1--HbFail;";
CM_ SG_ 1342 rc_lost "0--HB okay;
1--HbFail;
";
CM_ SG_ 1343 torque_wheels "Multiplied by active gear ratio
";
CM_ SG_ 1343 push2pass_budget_s "Time in seconds left in the total budget";
CM_ SG_ 1343 push2pass_active_app_limit "Active app limit (accelarator pedal position)";
CM_ BO_ 228 "Speed and heading data coming off of MyLaps racelink unit. Currently at 200 ms but WIP to bump up the update rate. This is for future improvement of purple flag behaviour by providing a redundant source of speed. ";
CM_ BO_ 226 "GPS data from MyLaps racelink unit. Currently at 200 ms but WIP to bump up the update rate.  ";
CM_ BO_ 1406 "AV24 vehicle will have virtual dash switches to perform low-level software functions like:

a) Traction Control
b) Pit Speed Limiter 
c) Push2Pass
d) Dynamic gain control for steering and brakes

The switch field has description of the type of switch (two-position, multi-pos etc.) and the corresponding function mapped to it in individual comments

CT are expected to respond to the switches in some form.

";
CM_ SG_ 1406 driver_traction_aim_switch "Switch Position: 0 (TC is OFF)
Switch Position: 1 (TC is ON and least aggressive - will allow the most wheel slip)
Swicth Position: 2 (TC is ON and less aggressive - will allow more wheel slip)
Switch Position: 3 (TC is ON and aggressive - will allow less wheel slip)
Switch Position: 4 (TC is ON and most aggressive - will allow the least wheel slip)";
CM_ SG_ 1406 driver_traction_range_switch "Switch Position: 0 (TC is ON and torque cut is moderate/default - Note: Traction Aim switch needs to be non-zero)
Switch Position: 1 (TC is ON and torque cut is most gradual i.e. it will allow most additional wheel slip on top of the aim)
Swicth Position: 2 (TC is ON and torque cut is less gradual than 1)
Switch Position: 3 (TC is ON and torque cut is aggressive)
Switch Position: 4 (TC is ON and torque cut is most aggressive. Most favorable in cold and damp conditions)";
CM_ SG_ 1406 brake_bias_aim_switch "Switch Position: 0 (Bias aimed is 50%)
Switch Position: 1 (Bias aimed is 51%)
Swicth Position: 2 (Bias aimed is 52%)
Switch Position: 3 (Bias aimed is 53%)
Switch Position: 4 (Bias aimed is 54%)
Switch Position: 5 (Bias aimed is 55%)
Swicth Position: 6 (Bias aimed is 56%)
Switch Position: 7 (Bias aimed is 57%)
Switch Position: 8 (Bias aimed is 58%)
Switch Position: 9 (Gives independant front and rear wheels brake control)";
CM_ SG_ 1406 drive_steering_gain_cntrl_switch "Switch Position: 0 (default raptor gains used - last saved values through calibration tool)
Switch Position: 1 (PID gains expected from the team if switched to 1) 

Safety: 

1) Nothing is transmitted on this signal - If nothing is ever transmitted - Raptor will read this as \"zero\" meaning default gains will be used.

2) Team transmits \"one\" but no gains are transmitted - Raptor will detect this and stick with default gains. The gains should always be transmitted if the switch is changed to \"one\". If not done correctly, can cause major system malfunction

3) Team switches back to \"zero\" but gains are still being published - This is fine and indeed prefered. It is suggested that the teams always transmit the gains (even if the dynamic gain control is not being used).  

Prefered mode of operation:
PID values and the switch can be parametrized and kept changeable thru base station.
Safety logic ensuring that the PID values are saturated to realistic values before sent to raptor.  ";
CM_ SG_ 1406 push2pass_switch "Switch Position: 0 (Driver does not command P2P)
Switch Position: 1 (Driver commands P2P)";
CM_ SG_ 1406 drive_steering_FF_cntrl_switch "Switch Position: 0 (Driver does not want/wants to operate with default raptor FF settings)
Switch Position: 1 (Driver wants to send FF gain online)";
CM_ BO_ 1450 "Long,Lat and Vertical G forces (Tx to Raptor at 100Hz) 
Source: Novatel Top/Bottom. Needed for Traction Control at MoTeC.  ";
CM_ BO_ 1250 "This message consists of key information pertaining to race control, scoring and sync check with rc basestation (heartbeat)
";
CM_ SG_ 1250 marelli_track_flag "last TRACK flag received id";
CM_ SG_ 1250 marelli_vehicle_flag "last CAR flag received id";
CM_ SG_ 1250 marelli_sector_flag "last SECTOR flag received id";
CM_ SG_ 1250 marelli_rc_base_sync_check "Sync check with RC base. This bit should is set to1 to enable transition to actuation test in race mode (meaning RC base is active).  If RC base experiences a consitent timeout of more than 10 seconds the bit will turn 0 ";
CM_ SG_ 1250 marelli_rc_lte_rssi "This is the signal strength of the LTE modem 
";
CM_ BO_ 1251 "This message consists of GPS info from Marelli. Not required for close monitoring but teams can use this info for other applications.

";
CM_ SG_ 1251 marelli_gps_lat "Latitude
";
CM_ SG_ 1251 marelli_gps_long "Longitude
";
CM_ BO_ 1405 "This message consists of ACKs related to Marelli Flags. The teams will be responsible to loop back the received flag (track,vehicle and sector) on this message in the relevant fields. Expected at 100 Hz.";
CM_ SG_ 1313 motor_duty_cycle_cmd "Commanded duty cycle by raptor";
CM_ SG_ 1313 motor_duty_cycle_fbk "reported duty cycle from SBW ECU";
CM_ SG_ 1313 motor_current_fbk "reported current draw fbk from SBW ECU";
CM_ SG_ 1313 sbw_ecu_voltage "reported voltage by SBW ECU";
CM_ SG_ 1313 sbw_ecu_temp "reported box temp by SBW ECU";
CM_ SG_ 1313 sbw_error_code "reported error code by SBW ECU";
CM_ SG_ 1313 sbw_motor_torque_estimate "estimated from a calibration between current draw and torque consumed";
CM_ BO_ 1314 "This message is related to the new BBW system
Signals give fbk on motor positions";
CM_ SG_ 1314 F_brk_pos_cmd "cmd motor position by raptor on fbrake (Scaling depends on min/max limits set on linear actuator)";
CM_ SG_ 1314 F_brk_pos_fbk "motor pos fbk from F brake";
CM_ SG_ 1314 R_brk_pos_cmd "cmd motor pos by raptor on rbrake (Scaling depends on min/max limits set on linear actuator)";
CM_ SG_ 1314 R_brk_pos_fbk "motor pos fbk from R brake";
CM_ BO_ 1350 "Lat and Long from Novatel receiver (For use at Marelli level)";
CM_ BO_ 1316 "Feedback related to individual controller contributions (P,I and D) of the steering controller on raptor";
CM_ BO_ 1344 "Boost Aim and Boost Pressure Added (units in PSI)";
CM_ SG_ 1344 boost_aim_psi "Feedback of the instantaneous boost aimed by MoTeC";
CM_ SG_ 1344 boost_press_psi "Feedback of instantaneous boost measured by MoTeC
";
CM_ SG_ 1344 intake_manifold_press_kPa "Feedback of intake manifold pressure measured by MoTeC";
CM_ SG_ 1344 intake_air_temp_degC "Feedback of intake air temp in degC as measured by MoTeC";
BA_DEF_  "BusType" STRING ;
BA_DEF_DEF_  "BusType" "CAN";
VAL_ 1343 driver_traction_aim_swicth_fbk -1 "Default" 0 "Zero" 1 "One" 2 "Two" 3 "Three" 4 "Four" 5 "Five" 6 "Six" 7 "Seven" 8 "Eight" 9 "Nine" ;
VAL_ 1343 driver_traction_range_switch_fbk -1 "Default" 0 "Zero" 1 "First" 2 "Second" 3 "Three" 4 "Four" 5 "Five" 6 "Six" 7 "Seven" 8 "Eight" 9 "Nine" ;
VAL_ 1343 push2pass_status 0 "Uninitialized" 1 "Not Permitted" 2 "Permitted" 3 "Active" 4 "Exhausted" 5 "Unlimited" 6 "Resetting" 7 "CoolDown" ;
VAL_ 1313 sbw_error_code 100 "Low Battery Voltage" 101 "Torque Sensor Disconnected" 102 "Torque Sensor Fault" 103 "Current Sensor Fault" 104 "Motor Power Fault" 105 "Motor Disconnected" 106 "Motor Shorted/Stalled" 109 "Over Current Detected" 110 "Over Temp Detected " ;
